# DA14531 register map
Vendor: Dialog; Series: DA14531; File version: 1.2
CPU: CM0 r1p0, little endian, MPU, FPU, 3 interrupt priority bits
Registers are 16-bit, read-write, reset 0x0 unless marked. A register's access mark holds for its fields unless they carry their own. Offsets are from the block's base; [hi:lo] are bit positions.

## TIMER1 — TIMER1 registers
Base 0x50004000
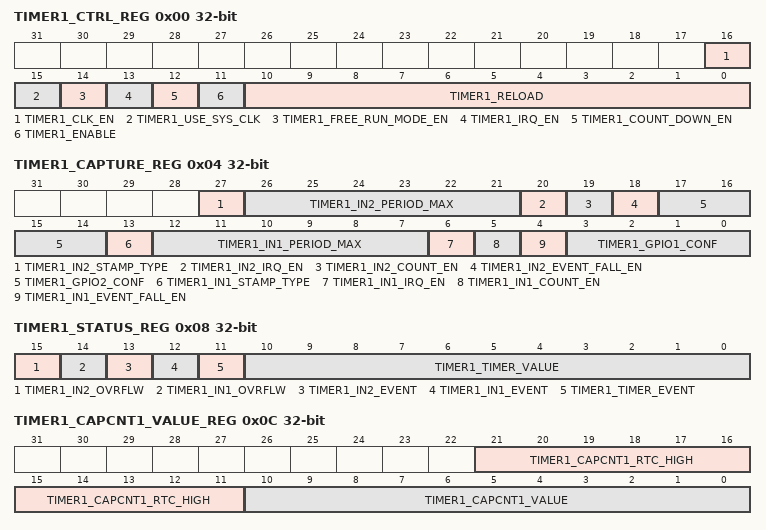
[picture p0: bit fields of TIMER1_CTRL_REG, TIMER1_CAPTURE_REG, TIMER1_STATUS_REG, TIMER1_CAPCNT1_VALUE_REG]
0x00 TIMER1_CTRL_REG 32-bit — Timer1 control register
  [16] TIMER1_CLK_EN — 0 = timer1 clock is disabled 1 = timer1 clock is enabled
  [15] TIMER1_USE_SYS_CLK — 0 = Timer1 use the clock LP clock 1 = Timer1 use the system clock
  [14] TIMER1_FREE_RUN_MODE_EN — Applicable when timer counts up 1 = timer1 goes to zero when it reaches the max value. 0 = timer1 goes to zero when it reaches the reload value.
  [13] TIMER1_IRQ_EN — 0 = timer1 IRQ masked 1 = timer1 IRQ unmasked
  [12] TIMER1_COUNT_DOWN_EN — 0 = timer1 counts up 1 = timer1 counts down
  [11] TIMER1_ENABLE — 0 = Timer1 disabled 1 = Timer1 enabled
  [10:0] TIMER1_RELOAD — Reload or max value in timer mode. Actual delay is the register value plus synchronization time (3 clock cycles)
0x04 TIMER1_CAPTURE_REG 32-bit — Timer1 Capture control register
  [27] TIMER1_IN2_STAMP_TYPE — 0 = On each event store the counter value 1 = On each event store the RTC time stamp
  [26:21] TIMER1_IN2_PERIOD_MAX — Gives the number of periods +1 of IN2, in which module counts
  [20] TIMER1_IN2_IRQ_EN — 1 = Interrupt is generated when capture is occurred or was counted TIMER1_IN2_PERIOD_MAX 0 = Interrupt is masked
  [19] TIMER1_IN2_COUNT_EN — 0 = Capture mode 1 = Count mode
  [18] TIMER1_IN2_EVENT_FALL_EN — 0 = Rising edge event 1 = Falling edge event it should be written when TIMER1_GPIO2_CONF=0 to prevent false events
  [17:14] TIMER1_GPIO2_CONF — 0,13,14,15 = IN2 is not used 1..12 = Defines the P0 pin (0..11) module will use as IN2
  [13] TIMER1_IN1_STAMP_TYPE — 0 = On each event store the counter value 1 = On each event store the RTC time stamp
  [12:7] TIMER1_IN1_PERIOD_MAX — Gives the number of periods +1 of IN1, in which module counts
  [6] TIMER1_IN1_IRQ_EN — 1 = Interrupt is generated when capture is occurred or was counted TIMER1_IN1_PERIOD_MAX 0 = Interrupt is masked
  [5] TIMER1_IN1_COUNT_EN — 0 = Capture mode 1 = Count mode
  [4] TIMER1_IN1_EVENT_FALL_EN — 0 = Rising edge event 1 = Falling edge event it should be written when TIMER1_GPIO1_CONF=0 to prevent false events
  [3:0] TIMER1_GPIO1_CONF — 0,13,14,15 = IN1 is not used 1..12 = Defines the P0 pin (0..11) module will use as IN1
0x08 TIMER1_STATUS_REG 32-bit — Timer1 counter value
  [15] TIMER1_IN2_OVRFLW ro — 1 = New IN2 event occurred while Interrupt was pending. TIMER1_CAPCNT2_VALUE_REG gives the time stamp of the first event.
  [14] TIMER1_IN1_OVRFLW ro — 1 = New IN1 event occurred while Interrupt was pending. TIMER1_CAPCNT1_VALUE_REG gives the time stamp of the first event.
  [13] TIMER1_IN2_EVENT ro — 1 = Pending Capture 2 interrupt. It has be clear writing 1 to TIMER1_CLR_IN2_EVENT
  [12] TIMER1_IN1_EVENT ro — 1 = Pending Capture 1 interrupt. It has be clear writing 1 to TIMER1_CLR_IN1_EVENT
  [11] TIMER1_TIMER_EVENT ro — 1 = Pending Timer interrupt. it has be clear writing 1' to TIMER1_CLR_TIMER_EVENT
  [10:0] TIMER1_TIMER_VALUE ro — Gives the current timer value
0x0C TIMER1_CAPCNT1_VALUE_REG 32-bit — Timer1 value for event on GPIO1
  [21:11] TIMER1_CAPCNT1_RTC_HIGH ro — In Counter mode : Not used In Capture mode: Gives the RTC time stamp (high part) when an IN1 event was occurred
  [10:0] TIMER1_CAPCNT1_VALUE ro — In Counter mode : Gives the number of timer clock cycles minus 1 which was measured during TIMER1_IN1_PERIOD_MAX periods of IN1 In Capture mode (TIMER1_IN1_STAMP_TYPE=0) : Gives the Counter value when an IN1 event was occurred In Capture mode (TIMER1_IN1_STAMP_TYPE=1) : Gives the RTC time stamp (low part) when an IN1 event was occurred
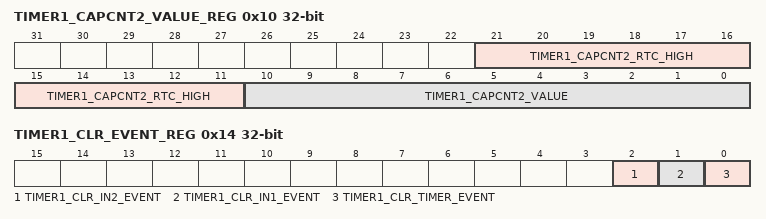
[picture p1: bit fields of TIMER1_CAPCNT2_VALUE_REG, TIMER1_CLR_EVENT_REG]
0x10 TIMER1_CAPCNT2_VALUE_REG 32-bit — Timer1 value for event on GPIO2
  [21:11] TIMER1_CAPCNT2_RTC_HIGH ro — In Counter mode : Not used In Capture mode: Gives the RTC time stamp (high part) when an IN2 event was occurred
  [10:0] TIMER1_CAPCNT2_VALUE ro — In Counter mode : Gives the number of timer clock cycles minus 1 which was measured during TIMER1_IN2_PERIOD_MAX periods of IN2 In Capture mode (TIMER1_IN2_STAMP_TYPE=0) : Gives the Counter value when an IN2 event was occurred In Capture mode (TIMER1_IN2_STAMP_TYPE=1) : Gives the RTC time stamp (low part) when an IN2 event was occurred
0x14 TIMER1_CLR_EVENT_REG 32-bit — Clear event register
  [2] TIMER1_CLR_IN2_EVENT — Write 1 to clear the TIMER1_IN2_EVENT and TIMER1_IN2_OVRFLW
  [1] TIMER1_CLR_IN1_EVENT — Write 1 to clear the TIMER1_IN1_EVENT and TIMER1_IN1_OVRFLW
  [0] TIMER1_CLR_TIMER_EVENT — Write 1 to clear the TIMER1_TIMER_EVENT
